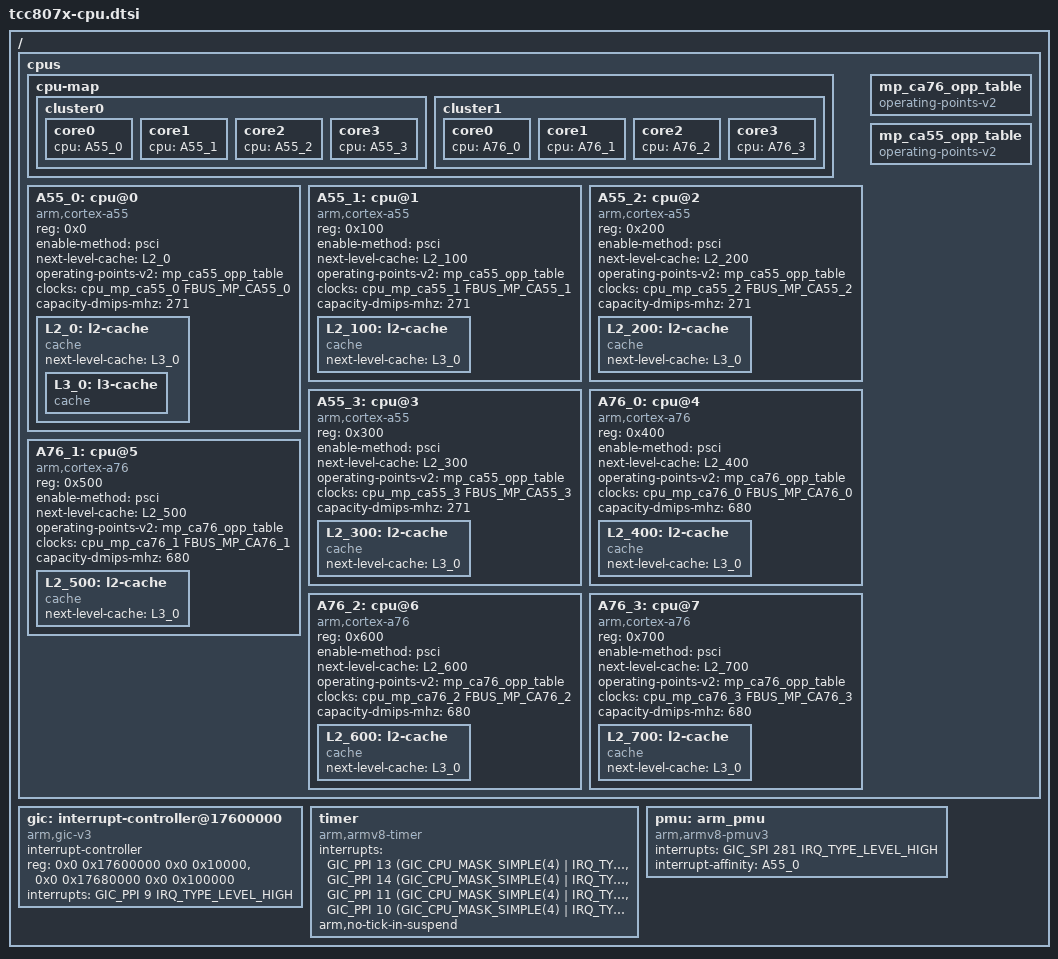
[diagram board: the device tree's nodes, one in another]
// SPDX-License-Identifier: (GPL-2.0-or-later OR MIT)
/*
 * Copyright (C) 2023 Telechips Inc.
 */

#include <dt-bindings/clock/telechips,tcc807x-clks.h>
#include <dt-bindings/interrupt-controller/arm-gic.h>

/ {
	cpus: cpus {
		#address-cells = <1>;
		#size-cells = <0>;

		cpu-map {
			cluster0 {
				core0 {
					cpu = <&A55_0>;
				};
				core1 {
					cpu = <&A55_1>;
				};
				core2 {
					cpu = <&A55_2>;
				};
				core3 {
					cpu = <&A55_3>;
				};
			};
			cluster1 {
				core0 {
					cpu = <&A76_0>;
				};
				core1 {
					cpu = <&A76_1>;
				};
				core2 {
					cpu = <&A76_2>;
				};
				core3 {
					cpu = <&A76_3>;
				};
			};
		};

		A55_0: cpu@0 {
			device_type = "cpu";
			compatible = "arm,cortex-a55";
			reg = <0x0>;
			enable-method = "psci";
			next-level-cache = <&L2_0>;
			#cooling-cells = <2>;
			operating-points-v2 = <&mp_ca55_opp_table>;
			clocks = <&cpu_mp_ca55_0 FBUS_MP_CA55_0>;
			capacity-dmips-mhz = <271>;

			L2_0: l2-cache {
				compatible = "cache";
				next-level-cache = <&L3_0>;
				L3_0: l3-cache {
					compatible = "cache";
				};
			};
		};

		A55_1: cpu@1 {
			device_type = "cpu";
			compatible = "arm,cortex-a55";
			reg = <0x100>;
			enable-method = "psci";
			next-level-cache = <&L2_100>;
			#cooling-cells = <2>;
			operating-points-v2 = <&mp_ca55_opp_table>;
			clocks = <&cpu_mp_ca55_1 FBUS_MP_CA55_1>;
			capacity-dmips-mhz = <271>;

			L2_100: l2-cache {
				compatible = "cache";
				next-level-cache = <&L3_0>;
			};
		};

		A55_2: cpu@2 {
			device_type = "cpu";
			compatible = "arm,cortex-a55";
			reg = <0x200>;
			enable-method = "psci";
			next-level-cache = <&L2_200>;
			#cooling-cells = <2>;
			operating-points-v2 = <&mp_ca55_opp_table>;
			clocks = <&cpu_mp_ca55_2 FBUS_MP_CA55_2>;
			capacity-dmips-mhz = <271>;

			L2_200: l2-cache {
				compatible = "cache";
				next-level-cache = <&L3_0>;
			};
		};

		A55_3: cpu@3 {
			device_type = "cpu";
			compatible = "arm,cortex-a55";
			reg = <0x300>;
			enable-method = "psci";
			next-level-cache = <&L2_300>;
			#cooling-cells = <2>;
			operating-points-v2 = <&mp_ca55_opp_table>;
			clocks = <&cpu_mp_ca55_3 FBUS_MP_CA55_3>;
			capacity-dmips-mhz = <271>;

			L2_300: l2-cache {
				compatible = "cache";
				next-level-cache = <&L3_0>;
			};
		};

		A76_0: cpu@4 {
			device_type = "cpu";
			compatible = "arm,cortex-a76";
			reg = <0x400>;
			enable-method = "psci";
			next-level-cache = <&L2_400>;
			operating-points-v2 = <&mp_ca76_opp_table>;
			#cooling-cells = <2>;
			clocks = <&cpu_mp_ca76_0 FBUS_MP_CA76_0>;
			capacity-dmips-mhz = <680>;

			L2_400: l2-cache {
				compatible = "cache";
				next-level-cache = <&L3_0>;
			};
		};

		A76_1: cpu@5 {
			device_type = "cpu";
			compatible = "arm,cortex-a76";
			reg = <0x500>;
			enable-method = "psci";
			next-level-cache = <&L2_500>;
			#cooling-cells = <2>;
			operating-points-v2 = <&mp_ca76_opp_table>;
			clocks = <&cpu_mp_ca76_1 FBUS_MP_CA76_1>;
			capacity-dmips-mhz = <680>;

			L2_500: l2-cache {
				compatible = "cache";
				next-level-cache = <&L3_0>;
			};
		};

		A76_2: cpu@6 {
			device_type = "cpu";
			compatible = "arm,cortex-a76";
			reg = <0x600>;
			enable-method = "psci";
			next-level-cache = <&L2_600>;
			#cooling-cells = <2>;
			operating-points-v2 = <&mp_ca76_opp_table>;
			clocks = <&cpu_mp_ca76_2 FBUS_MP_CA76_2>;
			capacity-dmips-mhz = <680>;

			L2_600: l2-cache {
				compatible = "cache";
				next-level-cache = <&L3_0>;
			};
		};

		A76_3: cpu@7 {
			device_type = "cpu";
			compatible = "arm,cortex-a76";
			reg = <0x700>;
			enable-method = "psci";
			next-level-cache = <&L2_700>;
			#cooling-cells = <2>;
			operating-points-v2 = <&mp_ca76_opp_table>;
			clocks = <&cpu_mp_ca76_3 FBUS_MP_CA76_3>;
			capacity-dmips-mhz = <680>;

			L2_700: l2-cache {
				compatible = "cache";
				next-level-cache = <&L3_0>;
			};
		};

		mp_ca76_opp_table: mp_ca76_opp_table {
			compatible = "operating-points-v2";
		};

		mp_ca55_opp_table: mp_ca55_opp_table {
			compatible = "operating-points-v2";
		};
	};

	gic: interrupt-controller@17600000 {
		compatible = "arm,gic-v3";
		#interrupt-cells = <3>;
		#address-cells = <2>;
		#size-cells = <2>;
		ranges;
		interrupt-controller;
		reg = <0x0 0x17600000 0x0 0x10000>,
		      <0x0 0x17680000 0x0 0x100000>;
		interrupts = <GIC_PPI 9 IRQ_TYPE_LEVEL_HIGH>;
	};

	timer: timer {
		compatible = "arm,armv8-timer";
		interrupts = <GIC_PPI 13 (GIC_CPU_MASK_SIMPLE(4) | IRQ_TYPE_LEVEL_LOW)>,
			     <GIC_PPI 14 (GIC_CPU_MASK_SIMPLE(4) | IRQ_TYPE_LEVEL_LOW)>,
			     <GIC_PPI 11 (GIC_CPU_MASK_SIMPLE(4) | IRQ_TYPE_LEVEL_LOW)>,
			     <GIC_PPI 10 (GIC_CPU_MASK_SIMPLE(4) | IRQ_TYPE_LEVEL_LOW)>;

		arm,no-tick-in-suspend;
	};

	pmu: arm_pmu {
		compatible = "arm,armv8-pmuv3";
		interrupts = <GIC_SPI 281 IRQ_TYPE_LEVEL_HIGH>;
		interrupt-affinity = <&A55_0>;
	};
};
